# PCIE0_DAT register map
Vendor: Texas Instruments
Registers are 32-bit, read-write, reset 0x0 unless marked. A register's access mark holds for its fields unless they carry their own. Offsets are as the file gives them; [hi:lo] are bit positions.

## PCIE0_DAT (part 3 of 6)
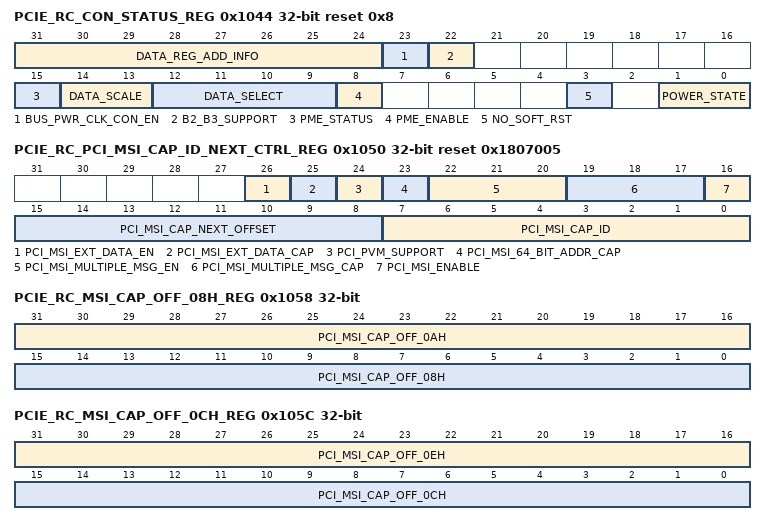
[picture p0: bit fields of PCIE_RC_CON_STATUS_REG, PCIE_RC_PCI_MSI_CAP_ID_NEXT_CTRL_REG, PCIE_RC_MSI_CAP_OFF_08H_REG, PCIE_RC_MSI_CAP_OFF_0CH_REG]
0x1044 PCIE_RC_CON_STATUS_REG access not given reset 0x8 — Power Management Control and Status Register. For a description of this standard PCIe register, see the PCI Express Specification.
  [31:24] DATA_REG_ADD_INFO ro — Power Data Information Register For a description of this standard PCIe register field, see the PCI Express Specification
  [23] BUS_PWR_CLK_CON_EN ro — Bus Power/Clock Control Enable For a description of this standard PCIe register field, see the PCI Express Specification
  [22] B2_B3_SUPPORT ro — B2B3 Support for D3hot For a description of this standard PCIe register field, see the PCI Express Specification
  [15] PME_STATUS — PME Status For a description of this standard PCIe register field, see the PCI Express Specification (access RW1C)
  [14:13] DATA_SCALE ro — Data Scaling Factor For a description of this standard PCIe register field, see the PCI Express Specification
  [12:9] DATA_SELECT ro — Data Select For a description of this standard PCIe register field, see the PCI Express Specification
  [8] PME_ENABLE rw — PME Enable For a description of this standard PCIe register field, see the PCI Express Specification The PMC registers this value under aux power Sometimes it might remember the old value, even if you try to clear it by writing '0' Note: This register field is sticky
  [3] NO_SOFT_RST ro — No soft Reset For a description of this standard PCIe register field, see the PCI Express Specification Note: The access attributes of this field are as follows: - Dbi: if [DBI_RO_WR_EN == 1] then R/W else R Note: This register field is sticky
  [1:0] POWER_STATE rw — Power State For a description of this standard PCIe register field, see the PCI Express Specification You can write to this register However, the read-back value is the actual power state, not the write value Note: The access attributes of this field are as follows: - Dbi: R/W
0x1050 PCIE_RC_PCI_MSI_CAP_ID_NEXT_CTRL_REG access per field reset 0x1807005 — MSI Capability ID, Next Pointer, Capability/Control Registers. For a description of this standard PCIe register, see the PCI Express Specification.
  [26] PCI_MSI_EXT_DATA_EN rw — Extended Message Data Enable For a description of this standard PCIe register, see the PCI-SIG ECN for Extended MSI Data, Feb 24, 2016, affecting PCI Express Specification Note: The access attributes of this field are as follows: - Dbi: PCI_MSI_CAP_ID_NEXT_CTRL_REGPCI_MSI_EXT_DATA_CAP ? RW : RO
  [25] PCI_MSI_EXT_DATA_CAP ro — Extended Message Data Capable For a description of this standard PCIe register, see the PCI-SIG ECN for Extended MSI Data, Feb 24, 2016, affecting PCI Express Specification Note: The access attributes of this field are as follows: - Dbi: if [DBI_RO_WR_EN == 1] then R/W else R Note: This register field is sticky
  [24] PCI_PVM_SUPPORT ro — MSI Per Vector Masking Capable For a description of this standard PCIe register field, see the PCI Express Specification
  [23] PCI_MSI_64_BIT_ADDR_CAP ro — MSI 64-bit Address Capable For a description of this standard PCIe register field, see the PCI Express Specification Note: The access attributes of this field are as follows: - Dbi: if [DBI_RO_WR_EN == 1] then R/W else R Note: This register field is sticky
  [22:20] PCI_MSI_MULTIPLE_MSG_EN rw — MSI Multiple Message Enable For a description of this standard PCIe register field, see the PCI Express Specification
  [19:17] PCI_MSI_MULTIPLE_MSG_CAP ro — MSI Multiple Message Capable For a description of this standard PCIe register field, see the PCI Express Specification Note: The access attributes of this field are as follows: - Dbi: if [DBI_RO_WR_EN == 1] then R/W else R Note: This register field is sticky
  [16] PCI_MSI_ENABLE rw — MSI Enable For a description of this standard PCIe register field, see the PCI Express Specification
  [15:8] PCI_MSI_CAP_NEXT_OFFSET ro — MSI Capability Next Pointer For a description of this standard PCIe register field, see the PCI Express Specification Note: The access attributes of this field are as follows: - Dbi: if [DBI_RO_WR_EN == 1] then R/W else R Note: This register field is sticky
  [7:0] PCI_MSI_CAP_ID ro — MSI Capability ID For a description of this standard PCIe register field, see the PCI Express Specification
0x1054 PCIE_RC_MSI_CAP_OFF_04H_REG access per field — MSI Message Lower Address Register. For a description of this standard PCIe register, see the PCI Express Specification.
  [31:2] PCI_MSI_CAP_OFF_04H rw — MSI Message Lower Address Field For a description of this standard PCIe register field, see the PCI Express Specification Note: The access attributes of this field are as follows: - Dbi: R/W
0x1058 PCIE_RC_MSI_CAP_OFF_08H_REG — For a 32 bit MSI Message, this register contains Data. For 64 bit it contains the Upper Address. For a description of this standard PCIe register, see the PCI Express Specification.
  [31:16] PCI_MSI_CAP_OFF_0AH — For a 32 bit MSI Message, this field contains Ext MSI Data For 64-bit it contains upper 16 bits of the Upper Address For a description of this standard PCIe register field, see the PCI Express Specification Note: The access attributes of this field are as follows: - Dbi: PCI_MSI_64_BIT_ADDR_CAP OR DEFAULT_EXT_MSI_DATA_CAPABLE ? R/W : R
  [15:0] PCI_MSI_CAP_OFF_08H — For a 32-bit MSI Message, this field contains Data For 64-bit it contains lower 16 bits of the Upper Address For a description of this standard PCIe register field, see the PCI Express Specification Note: The access attributes of this field are as follows: - Dbi: PCI_MSI_64_BIT_ADDR_CAP ? R/W : R
0x105C PCIE_RC_MSI_CAP_OFF_0CH_REG — For a 64 bit MSI Message, this register contains Data. For 32 bit, it contains Mask Bits if PVM enabled. For a description of this standard PCIe register, see the PCI Express Specification.
  [31:16] PCI_MSI_CAP_OFF_0EH — For a 64-bit MSI Message, this field contains Data For 32-bit, it contains the upper Mask Bits if PVM is enabled For a description of this standard PCIe register field, see the PCI Express Specification Note: The access attributes of this field are as follows: - Dbi: [!MSI_64_EN &amp;&amp; MSI_PVM_EN_VALUE] ? RW: MSI_64_EN &amp;&amp; DEFAULT_EXT_MSI_DATA_CAPABLE ? RW : RO
  [15:0] PCI_MSI_CAP_OFF_0CH — For a 64-bit MSI Message, this field contains Data For 32-bit, it contains the lower Mask Bits if PVM is enabled For a description of this standard PCIe register field, see the PCI Express Specification Note: The access attributes of this field are as follows: - Dbi: PCI_MSI_64_BIT_ADDR_CAP OR MSI_PVM_EN ? R/W : R
0x1060 PCIE_RC_MSI_CAP_OFF_10H_REG — Used for MSI when Vector Masking Capable. For 32 bit contains Pending Bits. For 64 bit, contains Mask Bits. For a description of this standard PCIe register, see the PCI Express Specification.
  [31:0] PCI_MSI_CAP_OFF_10H — Used for MSI when Vector Masking Capable For 32-bit contains Pending Bits For 64-bit, contains Mask Bits For a description of this standard PCIe register field, see the PCI Express Specification Note: The access attributes of this field are as follows: - Dbi: PCI_MSI_64_BIT_ADDR_CAP &amp;&amp; MSI_PVM_EN ? R/W : R
0x1064 PCIE_RC_MSI_CAP_OFF_14H_REG ro — Used for MSI 64 bit messaging when Vector Masking Capable. Contains Pending Bits. For a description of this standard PCIe register, see the PCI Express Specification.
  [31:0] PCI_MSI_CAP_OFF_14H — Used for MSI 64-bit messaging when Vector Masking Capable Contains Pending Bits For a description of this standard PCIe register field, see the PCI Express Specification
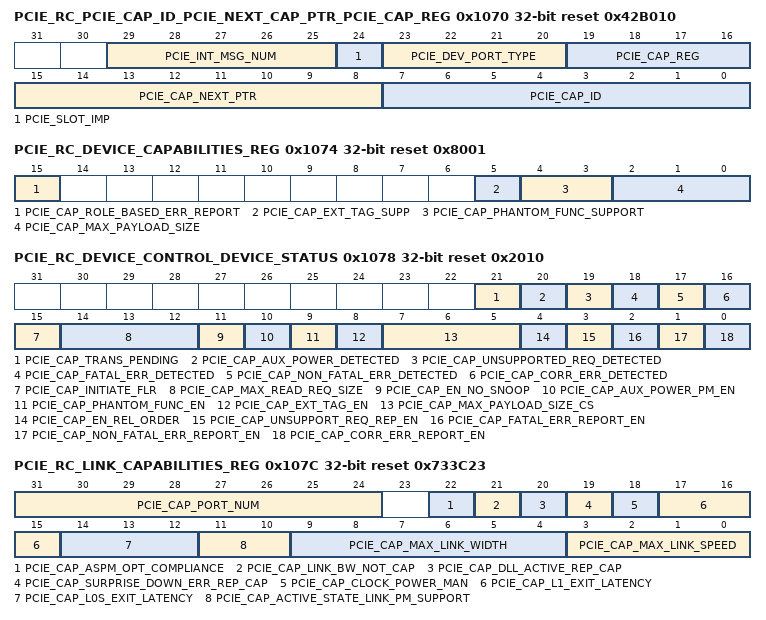
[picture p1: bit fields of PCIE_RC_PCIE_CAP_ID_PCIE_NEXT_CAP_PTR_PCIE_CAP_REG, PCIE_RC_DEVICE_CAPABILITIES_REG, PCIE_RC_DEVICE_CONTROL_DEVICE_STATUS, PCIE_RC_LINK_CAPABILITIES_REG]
0x1070 PCIE_RC_PCIE_CAP_ID_PCIE_NEXT_CAP_PTR_PCIE_CAP_REG ro reset 0x42B010 — PCI Express Capabilities, ID, Next Pointer Register. For a description of this standard PCIe register, see the PCI Express Specification.
  [29:25] PCIE_INT_MSG_NUM — PCIE Interrupt Message Number For a description of this standard PCIe register field, see the PCI Express Specification Note: The access attributes of this field are as follows: - Dbi: if [DBI_RO_WR_EN == 1] then R/W else R Note: This register field is sticky
  [24] PCIE_SLOT_IMP — PCIe Slot Implemented Valid For a description of this standard PCIe register field, see the PCI Express Specification Note: The access attributes of this field are as follows: - Dbi: if [DBI_RO_WR_EN == 1] then R/W else R
  [23:20] PCIE_DEV_PORT_TYPE — PCIE Device/PortType For a description of this standard PCIe register field, see the PCI Express Specification
  [19:16] PCIE_CAP_REG — PCIE Capability Version Number For a description of this standard PCIe register field, see the PCI Express Specification Note: This register field is sticky
  [15:8] PCIE_CAP_NEXT_PTR — PCIE Next Capability Pointer For a description of this standard PCIe register field, see the PCI Express Specification Note: The access attributes of this field are as follows: - Dbi: if [DBI_RO_WR_EN == 1] then R/W else R Note: This register field is sticky
  [7:0] PCIE_CAP_ID — PCIE Capability ID For a description of this standard PCIe register field, see the PCI Express Specification
0x1074 PCIE_RC_DEVICE_CAPABILITIES_REG ro reset 0x8001 — Device Capabilities Register. For a description of this standard PCIe register, see the PCI Express Specification.
  [15] PCIE_CAP_ROLE_BASED_ERR_REPORT — Role-based Error Reporting Implemented For a description of this standard PCIe register field, see the PCI Express Specification Note: The access attributes of this field are as follows: - Dbi: if [DBI_RO_WR_EN == 1] then R/W else R Note: This register field is sticky
  [5] PCIE_CAP_EXT_TAG_SUPP — Extended Tag Field Supported For a description of this standard PCIe register field, see the PCI Express Specification Note: The access attributes of this field are as follows: - Dbi: if [DBI_RO_WR_EN == 1] then R/W else R Note: This register field is sticky
  [4:3] PCIE_CAP_PHANTOM_FUNC_SUPPORT — Phantom Functions Supported For a description of this standard PCIe register field, see the PCI Express Specification Note: The access attributes of this field are as follows: - Dbi: if [DBI_RO_WR_EN == 1] then R/W else R Note: This register field is sticky
  [2:0] PCIE_CAP_MAX_PAYLOAD_SIZE — Max Payload Size Supported For a description of this standard PCIe register field, see the PCI Express Specification Note: The access attributes of this field are as follows: - Dbi: if [DBI_RO_WR_EN == 1] then R/W else R Note: This register field is sticky
0x1078 PCIE_RC_DEVICE_CONTROL_DEVICE_STATUS access not given reset 0x2010 — Device Control and Status Register. For a description of this standard PCIe register, see the PCI Express Specification.
  [21] PCIE_CAP_TRANS_PENDING ro — Transactions Pending Status For a description of this standard PCIe register field, see the PCI Express Specification
  [20] PCIE_CAP_AUX_POWER_DETECTED ro — Aux Power Detected Status For a description of this standard PCIe register field, see the PCI Express Specification This bit is derived by sampling the sys_aux_pwr_det input
  [19] PCIE_CAP_UNSUPPORTED_REQ_DETECTED — Unsupported Request Detected Status For a description of this standard PCIe register field, see the PCI Express Specification (access RW1C)
  [18] PCIE_CAP_FATAL_ERR_DETECTED — Fatal Error Detected Status For a description of this standard PCIe register field, see the PCI Express Specification (access RW1C)
  [17] PCIE_CAP_NON_FATAL_ERR_DETECTED — Non-Fatal Error Detected Status For a description of this standard PCIe register field, see the PCI Express Specification (access RW1C)
  [16] PCIE_CAP_CORR_ERR_DETECTED — Correctable Error Detected Status For a description of this standard PCIe register field, see the PCI Express Specification (access RW1C)
  [15] PCIE_CAP_INITIATE_FLR rw — Initiate Function Level Reset [for endpoints] For a description of this standard PCIe register field, see the PCI Express Specification
  [14:12] PCIE_CAP_MAX_READ_REQ_SIZE rw — Max Read Request Size For a description of this standard PCIe register field, see the PCI Express Specification
  [11] PCIE_CAP_EN_NO_SNOOP ro — Enable No Snoop For a description of this standard PCIe register field, see the PCI Express Specification Note: The access attributes of this field are as follows: - Dbi: R
  [10] PCIE_CAP_AUX_POWER_PM_EN rw — Aux Power PM Enable For a description of this standard PCIe register field, see the PCI Express Specification This bit is derived by sampling the sys_aux_pwr_det input Note: This register field is sticky
  [9] PCIE_CAP_PHANTOM_FUNC_EN ro — Phantom Functions Enable For a description of this standard PCIe register field, see the PCI Express Specification The write value is gated with the PCIE_CAP_PHANTOM_FUNC_SUPPORT field of
  [8] PCIE_CAP_EXT_TAG_EN ro — Extended Tag Field Enable For a description of this standard PCIe register field, see the PCI Express Specification The write value is gated with the PCIE_CAP_EXT_TAG_SUPP field of
  [7:5] PCIE_CAP_MAX_PAYLOAD_SIZE_CS rw — Max Payload Size Max_Payload_Size This field sets maximum TLP payload size for the Function Permissible values that can be programmed are indicated by the Max_Payload_Size Supported field [PCIE_CAP_MAX_PAYLOAD_SIZE] in the Device Capabilities register [
  [4] PCIE_CAP_EN_REL_ORDER rw — Enable Relaxed Ordering For a description of this standard PCIe register field, see the PCI Express Specification Note: The access attributes of this field are as follows: - Dbi: R/W
  [3] PCIE_CAP_UNSUPPORT_REQ_REP_EN rw — Unsupported Request Reporting Enable For a description of this standard PCIe register field, see the PCI Express Specification
  [2] PCIE_CAP_FATAL_ERR_REPORT_EN rw — Fatal Error Reporting Enable For a description of this standard PCIe register field, see the PCI Express Specification
  [1] PCIE_CAP_NON_FATAL_ERR_REPORT_EN rw — Non-fatal Error Reporting Enable For a description of this standard PCIe register field, see the PCI Express Specification
  [0] PCIE_CAP_CORR_ERR_REPORT_EN rw — Correctable Error Reporting Enable For a description of this standard PCIe register field, see the PCI Express Specification
0x107C PCIE_RC_LINK_CAPABILITIES_REG access per field reset 0x733C23 — Link Capabilities Register. For a description of this standard PCIe register, see the PCI Express Specification.
  [31:24] PCIE_CAP_PORT_NUM ro — Port Number For a description of this standard PCIe register field, see the PCI Express Specification Note: The access attributes of this field are as follows: - Dbi: if [DBI_RO_WR_EN == 1] then R/W else R
  [22] PCIE_CAP_ASPM_OPT_COMPLIANCE ro — ASPM Optionality Compliance For a description of this standard PCIe register field, see the PCI Express Specification Note: The access attributes of this field are as follows: - Dbi: if [DBI_RO_WR_EN == 1] then R/W else R
  [21] PCIE_CAP_LINK_BW_NOT_CAP ro — Link Bandwidth Notification Capable For a description of this standard PCIe register field, see the PCI Express Specification Note: The access attributes of this field are as follows: - Dbi: if [DBI_RO_WR_EN == 1] then R/W else R Note: This register field is sticky
  [20] PCIE_CAP_DLL_ACTIVE_REP_CAP ro — Data Link Layer Link Active Reporting Capable For a description of this standard PCIe register field, see the PCI Express Specification
  [19] PCIE_CAP_SURPRISE_DOWN_ERR_REP_CAP ro — Surprise Down Error Reporting Capable For a description of this standard PCIe register field, see the PCI Express Specification Note: The access attributes of this field are as follows: - Dbi: if [DBI_RO_WR_EN == 1] then R/W else R Note: This register field is sticky
  [18] PCIE_CAP_CLOCK_POWER_MAN ro — Clock Power Management For a description of this standard PCIe register field, see the PCI Express Specification Note: This register field is sticky
  [17:15] PCIE_CAP_L1_EXIT_LATENCY rw — L1 Exit Latency For a description of this standard PCIe register field, see the PCI Express Specification There are two each of these register fields, this one and a shadow one at the same address The Common Clock bit [PCIE_CAP_COMMON_CLK_CONFIG] of the Link Control Register [
  [14:12] PCIE_CAP_L0S_EXIT_LATENCY rw — LOs Exit Latency For a description of this standard PCIe register field, see the PCI Express Specification There are two each of these register fields, this one and a shadow one at the same address The Common Clock bit [PCIE_CAP_COMMON_CLK_CONFIG] of the Link Control Register [
  [11:10] PCIE_CAP_ACTIVE_STATE_LINK_PM_SUPPORT ro — Level of ASPM [Active State Power Management] Support For a description of this standard PCIe register field, see the PCI Express Specification Note: The access attributes of this field are as follows: - Dbi: if [DBI_RO_WR_EN == 1] then R/W else R Note: This register field is sticky
  [9:4] PCIE_CAP_MAX_LINK_WIDTH ro — Maximum Link Width For a description of this standard PCIe register field, see the PCI Express Specification In M-PCIe mode, the reset and dynamic values of this field are calculated by the controller Note: The access attributes of this field are as follows: - Dbi: if [DBI_RO_WR_EN == 1] then R/W else R Note: This register field is sticky
  [3:0] PCIE_CAP_MAX_LINK_SPEED ro — Maximum Link Speed For a description of this standard PCIe register field, see the PCI Express Specification In M-PCIe mode, the reset and dynamic values of this field are calculated by the controller Note: The access attributes of this field are as follows: - Dbi: if [DBI_RO_WR_EN == 1] then R/W else R Note: This register field is sticky
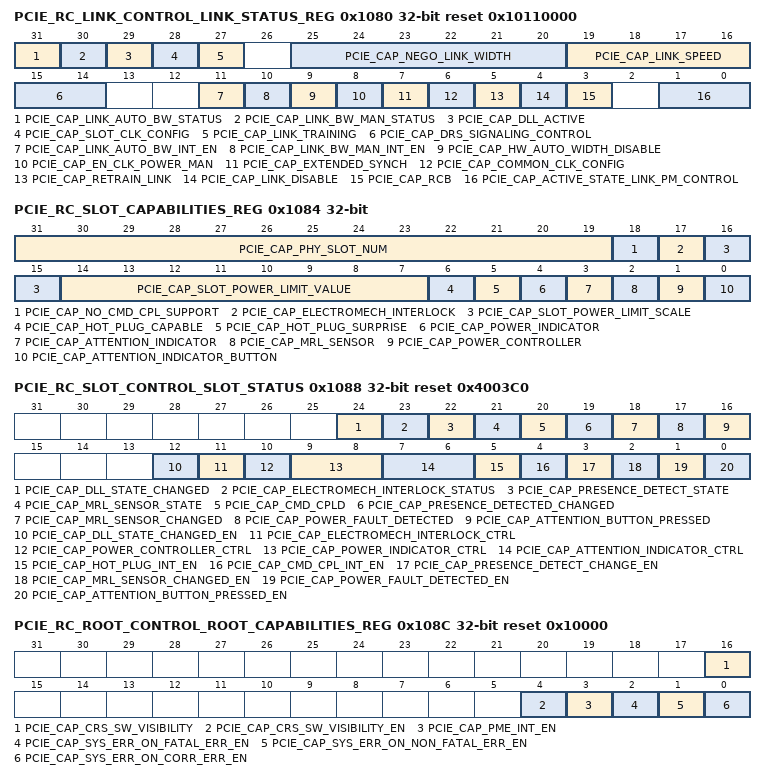
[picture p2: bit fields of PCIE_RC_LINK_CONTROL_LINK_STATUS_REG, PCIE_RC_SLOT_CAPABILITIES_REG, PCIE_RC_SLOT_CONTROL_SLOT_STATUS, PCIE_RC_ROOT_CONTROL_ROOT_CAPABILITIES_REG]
0x1080 PCIE_RC_LINK_CONTROL_LINK_STATUS_REG access not given reset 0x10110000 — Link Control and Status Register. For a description of this standard PCIe register, see the PCI Express Specification.
  [31] PCIE_CAP_LINK_AUTO_BW_STATUS — Link Autonomous Bandwidth Status For a description of this standard PCIe register field, see the PCI Express Specification The write value is gated with the PCIE_CAP_LINK_BW_NOT_CAP field in (access RW1C)
  [30] PCIE_CAP_LINK_BW_MAN_STATUS — Link Bandwidth Management Status For a description of this standard PCIe register field, see the PCI Express Specification The write value is gated with the PCIE_CAP_LINK_BW_NOT_CAP field in (access RW1C)
  [29] PCIE_CAP_DLL_ACTIVE ro — Data Link Layer Active For a description of this standard PCIe register field, see the PCI Express Specification
  [28] PCIE_CAP_SLOT_CLK_CONFIG ro — Slot Clock Configuration For a description of this standard PCIe register field, see the PCI Express Specification Note: The access attributes of this field are as follows: - Dbi: if [DBI_RO_WR_EN == 1] then R/W else R
  [27] PCIE_CAP_LINK_TRAINING ro — LTSSM is in Configuration or Recovery State For a description of this standard PCIe register field, see the PCI Express Specification
  [25:20] PCIE_CAP_NEGO_LINK_WIDTH ro — Negotiated Link Width For a description of this standard PCIe register field, see the PCI Express Specification
  [19:16] PCIE_CAP_LINK_SPEED ro — Current Link Speed For a description of this standard PCIe register field, see the PCI Express Specification
  [15:14] PCIE_CAP_DRS_SIGNALING_CONTROL rw — DRS Signaling Control For a description of this standard PCIe register field, see the PCI Express Specification Note: The access attributes of this field are as follows: - Dbi: LINK_CAPABILITIES2_REGDRS_SUPPORTED ? RW : RO
  [11] PCIE_CAP_LINK_AUTO_BW_INT_EN rw — Link Autonomous Bandwidth Management Interrupt Enable For a description of this standard PCIe register field, see the PCI Express Specification The write value is gated with the PCIE_CAP_LINK_BW_NOT_CAP field in
  [10] PCIE_CAP_LINK_BW_MAN_INT_EN rw — Link Bandwidth Management Interrupt Enable For a description of this standard PCIe register field, see the PCI Express Specification The write value is gated with the PCIE_CAP_LINK_BW_NOT_CAP field in
  [9] PCIE_CAP_HW_AUTO_WIDTH_DISABLE rw — Hardware Autonomous Width Disable For a description of this standard PCIe register field, see the PCI Express Specification Note: The access attributes of this field are as follows: - Dbi: R/W
  [8] PCIE_CAP_EN_CLK_POWER_MAN rw — Enable Clock Power Management For a description of this standard PCIe register field, see the PCI Express Specification The write value is gated with the PCIE_CAP_CLOCK_POWER_MAN field in
  [7] PCIE_CAP_EXTENDED_SYNCH rw — Extended Synch For a description of this standard PCIe register field, see the PCI Express Specification
  [6] PCIE_CAP_COMMON_CLK_CONFIG rw — Common Clock Configuration For a description of this standard PCIe register field, see the PCI Express Specification
  [5] PCIE_CAP_RETRAIN_LINK rw — Initiate Link Retrain For a description of this standard PCIe register field, see the PCI Express Specification Note: The access attributes of this field are as follows: - Dbi: see description
  [4] PCIE_CAP_LINK_DISABLE rw — Initiate Link Disable For a description of this standard PCIe register field, see the PCI Express Specification In a DSP that supports crosslink, the controller gates the write value with the CROSS_LINK_EN field in
  [3] PCIE_CAP_RCB ro — Read Completion Boundary [RCB] Note: The access attributes of this field are as follows: - Dbi: if [DBI_RO_WR_EN == 1] then R/W else R
  [1:0] PCIE_CAP_ACTIVE_STATE_LINK_PM_CONTROL rw — Active State Power Management [ASPM] Control Software must not enable L0s in either direction on a given Link unless components on both sides of the Link each support L0s otherwise, the result is undefined For a description of this standard PCIe register field, see the PCI Express Specification
0x1084 PCIE_RC_SLOT_CAPABILITIES_REG ro — Slot Capabilities Register. For a description of this standard PCIe register, see the PCI Express Specification.
  [31:19] PCIE_CAP_PHY_SLOT_NUM — Physical Slot Number For a description of this standard PCIe register field, see the PCI Express Specification Note: The access attributes of this field are as follows: - Dbi: if [DBI_RO_WR_EN == 1] then R/W else R
  [18] PCIE_CAP_NO_CMD_CPL_SUPPORT — No Command Completed Support For a description of this standard PCIe register field, see the PCI Express Specification Note: The access attributes of this field are as follows: - Dbi: if [DBI_RO_WR_EN == 1] then R/W else R
  [17] PCIE_CAP_ELECTROMECH_INTERLOCK — Electromechanical Interlock Present For a description of this standard PCIe register field, see the PCI Express Specification Note: The access attributes of this field are as follows: - Dbi: if [DBI_RO_WR_EN == 1] then R/W else R
  [16:15] PCIE_CAP_SLOT_POWER_LIMIT_SCALE — Slot Power Limit Scale For a description of this standard PCIe register field, see the PCI Express Specification Note: The access attributes of this field are as follows: - Dbi: if [DBI_RO_WR_EN == 1] then R/W else R
  [14:7] PCIE_CAP_SLOT_POWER_LIMIT_VALUE — Slot Power Limit Value For a description of this standard PCIe register field, see the PCI Express Specification Note: The access attributes of this field are as follows: - Dbi: if [DBI_RO_WR_EN == 1] then R/W else R
  [6] PCIE_CAP_HOT_PLUG_CAPABLE — Hot Plug Capable For a description of this standard PCIe register field, see the PCI Express Specification Note: The access attributes of this field are as follows: - Dbi: if [DBI_RO_WR_EN == 1] then R/W else R
  [5] PCIE_CAP_HOT_PLUG_SURPRISE — Hot Plug Surprise possible For a description of this standard PCIe register field, see the PCI Express Specification Note: The access attributes of this field are as follows: - Dbi: if [DBI_RO_WR_EN == 1] then R/W else R
  [4] PCIE_CAP_POWER_INDICATOR — Power Indicator Present For a description of this standard PCIe register field, see the PCI Express Specification Note: The access attributes of this field are as follows: - Dbi: if [DBI_RO_WR_EN == 1] then R/W else R
  [3] PCIE_CAP_ATTENTION_INDICATOR — Attention Indicator Present For a description of this standard PCIe register field, see the PCI Express Specification Note: The access attributes of this field are as follows: - Dbi: if [DBI_RO_WR_EN == 1] then R/W else R
  [2] PCIE_CAP_MRL_SENSOR — MRL Present For a description of this standard PCIe register field, see the PCI Express Specification Note: The access attributes of this field are as follows: - Dbi: if [DBI_RO_WR_EN == 1] then R/W else R
  [1] PCIE_CAP_POWER_CONTROLLER — Power Controller Present For a description of this standard PCIe register field, see the PCI Express Specification Note: The access attributes of this field are as follows: - Dbi: if [DBI_RO_WR_EN == 1] then R/W else R
  [0] PCIE_CAP_ATTENTION_INDICATOR_BUTTON — Attention Button Present For a description of this standard PCIe register field, see the PCI Express Specification Note: The access attributes of this field are as follows: - Dbi: if [DBI_RO_WR_EN == 1] then R/W else R
0x1088 PCIE_RC_SLOT_CONTROL_SLOT_STATUS access not given reset 0x4003C0 — Slot Control and Status Register. For a description of this standard PCIe register, see the PCI Express Specification.
  [24] PCIE_CAP_DLL_STATE_CHANGED — Data Link Layer State Changed For a description of this standard PCIe register field, see the PCI Express Specification (access RW1C)
  [23] PCIE_CAP_ELECTROMECH_INTERLOCK_STATUS ro — Electromechanical Interlock Status For a description of this standard PCIe register field, see the PCI Express Specification
  [22] PCIE_CAP_PRESENCE_DETECT_STATE ro — Presence Detect State For a description of this standard PCIe register field, see the PCI Express Specification Note: The access attributes of this field are as follows: - Dbi: R
  [21] PCIE_CAP_MRL_SENSOR_STATE ro — MRL Sensor State For a description of this standard PCIe register field, see the PCI Express Specification
  [20] PCIE_CAP_CMD_CPLD — Command Completed For a description of this standard PCIe register field, see the PCI Express Specification (access RW1C)
  [19] PCIE_CAP_PRESENCE_DETECTED_CHANGED — Presence Detect Changed For a description of this standard PCIe register field, see the PCI Express Specification (access RW1C)
  [18] PCIE_CAP_MRL_SENSOR_CHANGED — MRL Sensor Changed For a description of this standard PCIe register field, see the PCI Express Specification (access RW1C)
  [17] PCIE_CAP_POWER_FAULT_DETECTED — Power Fault Detected For a description of this standard PCIe register field, see the PCI Express Specification (access RW1C)
  [16] PCIE_CAP_ATTENTION_BUTTON_PRESSED — Attention Button Pressed For a description of this standard PCIe register field, see the PCI Express Specification (access RW1C)
  [12] PCIE_CAP_DLL_STATE_CHANGED_EN rw — Data Link Layer State Changed Enable For a description of this standard PCIe register field, see the PCI Express Specification
  [11] PCIE_CAP_ELECTROMECH_INTERLOCK_CTRL rw — Electromechanical Interlock Control For a description of this standard PCIe register field, see the PCI Express Specification
  [10] PCIE_CAP_POWER_CONTROLLER_CTRL rw — Power Controller Control For a description of this standard PCIe register field, see the PCI Express Specification
  [9:8] PCIE_CAP_POWER_INDICATOR_CTRL rw — Power Indicator Control For a description of this standard PCIe register field, see the PCI Express Specification
  [7:6] PCIE_CAP_ATTENTION_INDICATOR_CTRL rw — Attention Indicator Control For a description of this standard PCIe register field, see the PCI Express Specification
  [5] PCIE_CAP_HOT_PLUG_INT_EN rw — Hot Plug Interrupt Enable For a description of this standard PCIe register field, see the PCI Express Specification
  [4] PCIE_CAP_CMD_CPL_INT_EN rw — Command Completed Interrupt Enable For a description of this standard PCIe register field, see the PCI Express Specification Write value is gated with PCIE_CAP_NO_CMD_CPL_SUPPORT field in
  [3] PCIE_CAP_PRESENCE_DETECT_CHANGE_EN rw — Presence Detect Changed Enable For a description of this standard PCIe register field, see the PCI Express Specification
  [2] PCIE_CAP_MRL_SENSOR_CHANGED_EN rw — MRL Sensor Changed Enable For a description of this standard PCIe register field, see the PCI Express Specification
  [1] PCIE_CAP_POWER_FAULT_DETECTED_EN rw — Power Fault Detected Enable For a description of this standard PCIe register field, see the PCI Express Specification
  [0] PCIE_CAP_ATTENTION_BUTTON_PRESSED_EN rw — Attention Button Pressed Enable For a description of this standard PCIe register field, see the PCI Express Specification
0x108C PCIE_RC_ROOT_CONTROL_ROOT_CAPABILITIES_REG access per field reset 0x10000 — Root Control and Capabilities Register. For a description of this standard PCIe register, see the PCI Express Specification.
  [16] PCIE_CAP_CRS_SW_VISIBILITY ro — CRS Software Visibility Capable For a description of this standard PCIe register field, see the PCI Express Specification Note: The access attributes of this field are as follows: - Dbi: if [DBI_RO_WR_EN == 1] then R/W [Sticky] else R [Sticky] Note: This register field is sticky
  [4] PCIE_CAP_CRS_SW_VISIBILITY_EN rw — Configuration Request Retry Status [CRS] Software Visibility Enable For a description of this standard PCIe register field, see the PCI Express Specification Note: The access attributes of this field are as follows: - Dbi: ROOT_CONTROL_ROOT_CAPABILITIES_REGPCIE_CAP_CRS_SW_VISIBILITY ? RW : RO
  [3] PCIE_CAP_PME_INT_EN rw — PME Interrupt Enable For a description of this standard PCIe register field, see the PCI Express Specification
  [2] PCIE_CAP_SYS_ERR_ON_FATAL_ERR_EN rw — System Error on Fatal Error Enable For a description of this standard PCIe register field, see the PCI Express Specification
  [1] PCIE_CAP_SYS_ERR_ON_NON_FATAL_ERR_EN rw — System Error on Non-fatal Error Enable For a description of this standard PCIe register field, see the PCI Express Specification
  [0] PCIE_CAP_SYS_ERR_ON_CORR_ERR_EN rw — System Error on Correctable Error Enable For a description of this standard PCIe register field, see the PCI Express Specification
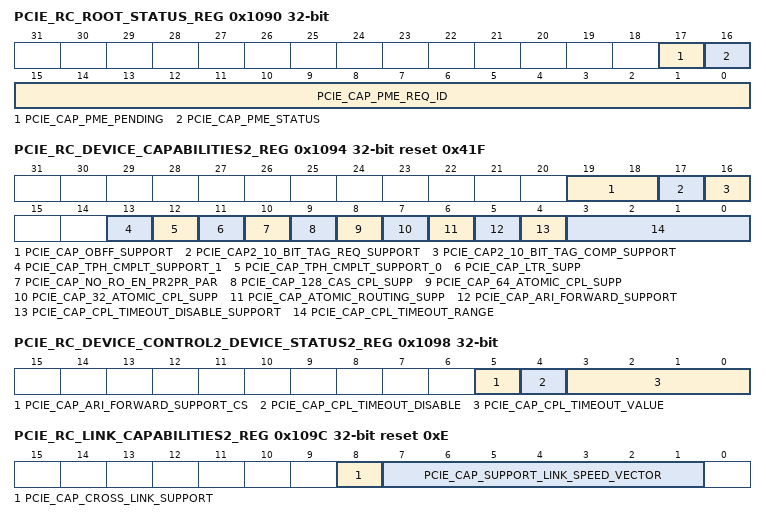
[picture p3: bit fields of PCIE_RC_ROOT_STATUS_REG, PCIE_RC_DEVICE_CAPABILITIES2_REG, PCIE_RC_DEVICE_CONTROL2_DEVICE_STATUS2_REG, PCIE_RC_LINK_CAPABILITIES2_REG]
0x1090 PCIE_RC_ROOT_STATUS_REG access not given — Root Status Register. For a description of this standard PCIe register, see the PCI Express Specification.
  [17] PCIE_CAP_PME_PENDING ro — PME Pending For a description of this standard PCIe register field, see the PCI Express Specification
  [16] PCIE_CAP_PME_STATUS — PME Status For a description of this standard PCIe register field, see the PCI Express Specification (access RW1C)
  [15:0] PCIE_CAP_PME_REQ_ID ro — PME Requester ID For a description of this standard PCIe register field, see the PCI Express Specification
0x1094 PCIE_RC_DEVICE_CAPABILITIES2_REG ro reset 0x41F — Device Capabilities 2 Register. For a description of this standard PCIe register, see the PCI Express Specification.
  [19:18] PCIE_CAP_OBFF_SUPPORT — [OBFF] Optimized Buffer Flush/fill Supported For a description of this standard PCIe register field, see the PCI Express Specification
  [17] PCIE_CAP2_10_BIT_TAG_REQ_SUPPORT — 10-Bit Tag Requester Supported For a description of this standard PCIe register field, see the PCI Express Base Specification 40
  [16] PCIE_CAP2_10_BIT_TAG_COMP_SUPPORT — 10-Bit Tag Completer Supported For a description of this standard PCIe register field, see the PCI Express Base Specification 40
  [13] PCIE_CAP_TPH_CMPLT_SUPPORT_1 — TPH Completer Supported Bit 1 For a description of this standard PCIe register field, see the PCI Express Specification
  [12] PCIE_CAP_TPH_CMPLT_SUPPORT_0 — TPH Completer Supported Bit 0 For a description of this standard PCIe register field, see the PCI Express Specification
  [11] PCIE_CAP_LTR_SUPP — LTR Mechanism Supported For a description of this standard PCIe register field, see the PCI Express Specification
  [10] PCIE_CAP_NO_RO_EN_PR2PR_PAR — No Relaxed Ordering Enabled PR-PR Passing For a description of this standard PCIe register field, see the PCI Express Specification
  [9] PCIE_CAP_128_CAS_CPL_SUPP — 128 Bit CAS Completer Supported For a description of this standard PCIe register field, see the PCI Express Specification
  [8] PCIE_CAP_64_ATOMIC_CPL_SUPP — 64 Bit AtomicOp Completer Supported For a description of this standard PCIe register field, see the PCI Express Specification
  [7] PCIE_CAP_32_ATOMIC_CPL_SUPP — 32 Bit AtomicOp Completer Supported For a description of this standard PCIe register field, see the PCI Express Specification
  [6] PCIE_CAP_ATOMIC_ROUTING_SUPP — Atomic Operation Routing Supported For a description of this standard PCIe register field, see the PCI Express Specification
  [5] PCIE_CAP_ARI_FORWARD_SUPPORT — ARI Forwarding Supported For a description of this standard PCIe register field, see the PCI Express Specification
  [4] PCIE_CAP_CPL_TIMEOUT_DISABLE_SUPPORT — Completion Timeout Disable Supported For a description of this standard PCIe register field, see the PCI Express Specification
  [3:0] PCIE_CAP_CPL_TIMEOUT_RANGE — Completion Timeout Ranges Supported For a description of this standard PCIe register field, see the PCI Express Specification
0x1098 PCIE_RC_DEVICE_CONTROL2_DEVICE_STATUS2_REG access per field — Device Control 2 and Status 2 Register. For a description of this standard PCIe register, see the PCI Express Specification.
  [5] PCIE_CAP_ARI_FORWARD_SUPPORT_CS ro — ARI Forwarding Enable For a description of this standard PCIe register field, see the PCI Express Specification Note: The access attributes of this field are as follows: - Dbi: R/W
  [4] PCIE_CAP_CPL_TIMEOUT_DISABLE rw — Completion Timeout Disable For a description of this standard PCIe register field, see the PCI Express Specification
  [3:0] PCIE_CAP_CPL_TIMEOUT_VALUE rw — Completion Timeout Value For a description of this standard PCIe register field, see the PCI Express Specification Note: The access attributes of this field are as follows: - Dbi: R/W
0x109C PCIE_RC_LINK_CAPABILITIES2_REG ro reset 0xE — Link Capabilities 2 Register. For a description of this standard PCIe register, see the PCI Express Specification.
  [8] PCIE_CAP_CROSS_LINK_SUPPORT — Cross Link Supported For a description of this standard PCIe register field, see the PCI Express Specification
  [7:1] PCIE_CAP_SUPPORT_LINK_SPEED_VECTOR — Supported Link Speeds Vector For a description of this standard PCIe register field, see the PCI Express Specification This field has a default of [PCIE_CAP_MAX_LINK_SPEED == 0100] ? 0001111 : [PCIE_CAP_MAX_LINK_SPEED == 0011] ? 0000111 : [PCIE_CAP_MAX_LINK_SPEED == 0010] ? 0000011 : 0000001 where PCIE_CAP_MAX_LINK_SPEED is a field in the PCIE_RC_LINK_CAPABILITIES_REG register
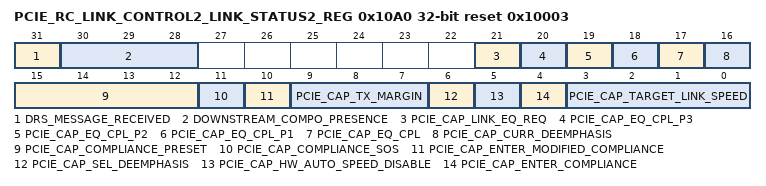
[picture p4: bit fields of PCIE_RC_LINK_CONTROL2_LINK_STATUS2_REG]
0x10A0 PCIE_RC_LINK_CONTROL2_LINK_STATUS2_REG access not given reset 0x10003 — Link Control 2 and Status 2 Register. For a description of this standard PCIe register, see the PCI Express Specification.
  [31] DRS_MESSAGE_RECEIVED ro — DRS Message Received For a description of this standard PCIe register field, see the PCI Express Base Specification 40 Note: The access attributes of this field are as follows: - Dbi: RW1C
  [30:28] DOWNSTREAM_COMPO_PRESENCE ro — Downstream Component Presence For a description of this standard PCIe register field, see the PCI Express Base Specification 40
  [21] PCIE_CAP_LINK_EQ_REQ — Link Equalization Request 80GT/s For a description of this standard PCIe register field, see the PCI Express Specification (access RW1C)
  [20] PCIE_CAP_EQ_CPL_P3 ro — Equalization 80GT/s Phase 3 Successful For a description of this standard PCIe register field, see the PCI Express Specification Note: This register field is sticky
  [19] PCIE_CAP_EQ_CPL_P2 ro — Equalization 80GT/s Phase 2 Successful For a description of this standard PCIe register field, see the PCI Express Specification Note: This register field is sticky
  [18] PCIE_CAP_EQ_CPL_P1 ro — Equalization 80GT/s Phase 1 Successful For a description of this standard PCIe register field, see the PCI Express Specification Note: This register field is sticky
  [17] PCIE_CAP_EQ_CPL ro — Equalization 80GT/s Complete For a description of this standard PCIe register field, see the PCI Express Specification Note: This register field is sticky
  [16] PCIE_CAP_CURR_DEEMPHASIS ro — Current De-emphasis Level For a description of this standard PCIe register field, see the PCI Express Specification In M-PCIe mode this register is always 0x0 In C-PCIe mode, its contents are derived by sampling the PIPE
  [15:12] PCIE_CAP_COMPLIANCE_PRESET rw — Sets Compliance Preset/De-emphasis for 5 GT/s and 8 GT/s For a description of this standard PCIe register field, see the PCI Express Specification Note: The access attributes of this field are as follows: - Dbi: R/W [sticky] Note: This register field is sticky
  [11] PCIE_CAP_COMPLIANCE_SOS rw — Sets Compliance Skip Ordered Sets transmission For a description of this standard PCIe register field, see the PCI Express Specification Note: The access attributes of this field are as follows: - Dbi: R/W [sticky] Note: This register field is sticky
  [10] PCIE_CAP_ENTER_MODIFIED_COMPLIANCE rw — Enter Modified Compliance For a description of this standard PCIe register field, see the PCI Express Specification Note: The access attributes of this field are as follows: - Dbi: R [sticky] Note: This register field is sticky
  [9:7] PCIE_CAP_TX_MARGIN rw — Controls Transmit Margin for Debug or Compliance For a description of this standard PCIe register field, see the PCI Express Specification Note: This register field is sticky
  [6] PCIE_CAP_SEL_DEEMPHASIS ro — Controls Selectable De-emphasis for 5 GT/s For a description of this standard PCIe register field, see the PCI Express Specification Note: The access attributes of this field are as follows: - Dbi: if [DBI_RO_WR_EN == 1] then R/W[sticky] else R[sticky] Note: This register field is sticky
  [5] PCIE_CAP_HW_AUTO_SPEED_DISABLE rw — Hardware Autonomous Speed Disable For a description of this standard PCIe register field, see the PCI Express Specification Note: The access attributes of this field are as follows: - Dbi: R [sticky] Note: This register field is sticky
  [4] PCIE_CAP_ENTER_COMPLIANCE rw — Enter Compliance Mode For a description of this standard PCIe register field, see the PCI Express Specification Note: This register field is sticky
  [3:0] PCIE_CAP_TARGET_LINK_SPEED rw — Target Link Speed For a description of this standard PCIe register field, see the PCI Express Specification In M-PCIe mode, the contents of this field are derived from other registers Note: This register field is sticky
